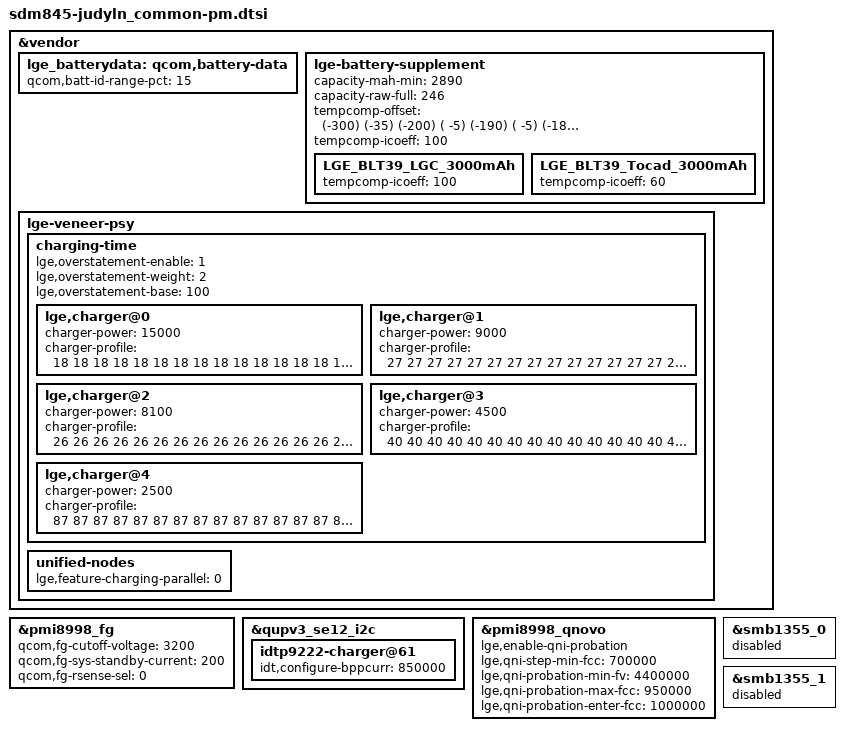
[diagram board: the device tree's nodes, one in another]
/* Copyright (c) 2017, The Linux Foundation. All rights reserved.
 *
 * This program is free software; you can redistribute it and/or modify
 * it under the terms of the GNU General Public License version 2 and
 * only version 2 as published by the Free Software Foundation.
 *
 * This program is distributed in the hope that it will be useful,
 * but WITHOUT ANY WARRANTY; without even the implied warranty of
 * MERCHANTABILITY or FITNESS FOR A PARTICULAR PURPOSE.  See the
 * GNU General Public License for more details.
 */

#include "../sdm845-judy_common/sdm845-judy_common-pm.dtsi"

&vendor {
	lge_batterydata: qcom,battery-data {
		qcom,batt-id-range-pct = <15>;

		#include "../../sdm845-battery/LGE_BLT39_LGC_3000mAh.dtsi"
		#include "../../sdm845-battery/LGE_BLT39_Tocad_3000mAh.dtsi"
	};

	lge-battery-supplement {
		capacity-mah-min = <2890>;
		capacity-raw-full = <246>;

		/* format : (temp index) (temp delta) */
		tempcomp-offset = <
			(-300) (-35)
			(-200) ( -5)
			(-190) ( -5)
			(-180)    0
			(-170)    5
			(-160)   10
			(-150)   25
			(-100)   29
			( -50)   36
			    0    38
			   50    25
			  100    21
			  150    12
			  200     2
			  250  (-10)
			  300  (-22)
			  350  (-34)
			  400  (-41)
			  450  (-48)
			  500  (-52)
			  550  (-43)
			  600  (-34)
			  700  (-10)
			  800  (-10)
			  900  (-10)
		>;
		tempcomp-icoeff = <100>;

		/* overriding by battery type */
		LGE_BLT39_LGC_3000mAh {
			tempcomp-icoeff = <100>;
		};
		LGE_BLT39_Tocad_3000mAh {
			tempcomp-icoeff = <60>;
		};
	};

	lge-veneer-psy {
		charging-time {
			#address-cells = <1>;
			#size-cells = <0>;

			lge,overstatement-enable = <1>;
			lge,overstatement-weight = <2>;
			lge,overstatement-base = <100>;

			lge,charger@0 {		//  fast charger: 9000mV * 1660mA or 5000mV * 3000mA
				charger-power = <15000>;
				charger-profile = <
					18  18  18  18  18  18  18  18  18  18  18  18  18  18  18  18
					18  18  18  18  18  18  18  18  18  18  18  18  18  18  18  18
					18  18  18  18  18  18  18  18  18  18  18  18  18  18  18  18
					18  18  18  18  18  18  18  18  18  18  18  18  18  18  18  18
					18  18  18  18  18  18  18  18  18  18  18  18  18  18  18  18
					18  18  18  18  18  18  18  18  18  18  18  18  18  18  18  18
					18  18  18  18  18  18  18  18  18  18  18  18  18  18  18  18
					18  18  18  18  18  18  18  18  18  18  18  18  18  18  18  18
					18  18  18  18  18  18  18  18  18  18  18  18  18  18  18  18
					18  18  18  18  18  18  18  18  18  18  18  18  18  18  18  18
					18  18  18  18  18  18  18  18  21  21  21  21  21  21  21  21
					21  21  21  21  21  21  21  21  21  21  21  21  21  24  24  24
					24  24  24  24  24  24  24  24  24  24  24  24  28  28  28  28
					28  28  28  28  28  29  29  38  38  38  38  38  38  38  38  38
					38  43  43  44  45  46  46  46  49  51  54  56  59  64  68  72
					76  82  88  94 101 110 113 113 113 113 113 113 113 113 113 113
				>;
			};
			lge,charger@1 {		//  dcp charger: 5000mV * 1800mA = 9W
				charger-power = <9000>;
				charger-profile = <
					27  27  27  27  27  27  27  27  27  27  27  27  27  27  27  27
					27  27  28  28  28  28  28  28  28  28  28  28  28  28  28  28
					28  28  28  28  28  28  28  28  28  28  28  28  28  28  28  28
					28  28  28  28  28  28  28  28  28  28  28  28  28  28  28  28
					28  28  28  28  29  29  29  29  29  29  29  29  29  29  29  29
					29  29  29  29  29  29  29  29  29  29  29  29  29  29  29  29
					29  29  29  29  29  29  29  29  29  29  29  29  29  29  29  29
					29  29  29  30  30  30  30  30  30  30  30  30  30  30  30  30
					30  30  30  30  30  30  30  30  30  30  30  30  30  30  30  30
					30  30  30  30  30  30  30  30  30  30  30  30  30  30  30  31
					31  31  31  31  31  31  31  31  31  31  31  31  31  31  31  31
					31  31  31  31  31  31  31  31  31  31  31  31  31  31  31  31
					31  31  31  31  31  31  31  31  32  32  32  32  32  33  33  33
					34  34  35  35  35  36  36  36  37  37  38  38  39  40  40  42
					43  44  44  45  46  47  48  48  51  52  55  57  60  65  69  73
					77  83  89  95 102 111 115 115 115 115 115 115 115 115 115 115
				>;
			};
			lge,charger@2 {		// EPP wireless charger: 9000mV * 900mA = 8.1W
				charger-power = <8100>;
				charger-profile = <
					26  26  26  26  26  26  26  26  26  26  26  26  26  26  26  26
					26  26  26  26  26  26  26  26  26  26  26  26  26  26  26  26
					26  26  26  26  26  26  26  26  26  26  26  26  26  26  26  26
					26  26  26  26  26  26  26  26  26  26  26  26  26  26  26  26
					26  26  26  26  26  26  26  26  26  26  26  26  26  26  26  26
					26  26  26  26  26  26  26  26  26  26  26  26  26  26  26  27
					27  27  27  27  27  27  27  27  27  27  27  27  27  27  27  27
					27  27  27  27  27  27  27  27  27  27  27  27  27  27  27  27
					27  27  27  27  27  27  27  27  27  27  27  27  27  27  27  27
					27  27  27  27  27  27  27  27  28  28  28  28  28  28  28  28
					28  28  28  28  28  28  28  28  28  28  28  28  28  28  28  28
					28  28  28  28  28  28  28  28  28  28  28  28  28  28  28  28
					28  28  28  28  28  28  28  28  28  28  28  28  28  29  29  29
					29  29  29  30  30  31  31  32  33  34  35  35  36  37  38  40
					41  42  43  45  47  48  50  52  54  56  59  61  64  67  71  75
					79  84  89  95 102 110 120 120 120 120 120 120 120 120 120 120
				>;
			};
			lge,charger@3 {		// BPP wireless charger: 5000mV * 900mA = 4.5W
				charger-power = <4500>;
				charger-profile = <
					40  40  40  40  40  40  40  40  40  40  40  40  40  40  40  40
					40  40  41  41  41  41  41  41  41  41  41  41  41  41  41  41
					41  41  41  41  41  41  41  41  41  41  41  41  41  42  42  42
					42  42  42  42  42  42  42  42  42  42  42  42  42  42  42  42
					42  42  42  42  42  43  43  43  43  43  43  43  43  43  43  43
					43  43  43  43  43  43  43  43  43  43  43  43  43  43  44  44
					44  44  44  44  44  44  44  44  44  44  44  44  44  44  44  44
					44  44  44  44  45  45  45  45  45  45  45  45  45  45  45  45
					45  45  45  45  45  45  45  45  45  45  46  46  46  46  46  46
					46  46  46  46  46  46  46  46  46  46  46  46  46  46  46  47
					47  47  47  47  47  47  47  47  47  47  47  47  47  47  47  47
					47  47  47  48  48  48  48  48  48  48  48  48  48  48  48  48
					48  48  48  48  48  48  49  49  49  49  49  49  49  49  49  49
					49  49  49  49  49  49  49  49  50  50  50  50  50  50  50  50
					50  50  49  50  50  51  52  54  56  59  61  64  67  70  74  78
					82  87  93  99 106 115 125 125 125 125 125 125 125 125 125 125
				>;
			};
			lge,charger@4 {		// SDP: 5000mV * 500mA = 2.5W
				charger-power = <2500>;
				charger-profile = <
					87  87  87  87  87  87  87  87  87  87  87  87  87  87  87  87
					87  87  87  87  87  87  87  87  87  87  87  87  87  87  87  87
					87  87  87  87  87  87  87  87  87  87  87  87  87  87  87  87
					87  87  87  87  87  87  87  87  87  87  87  87  87  87  87  87
					87  87  87  87  87  87  87  87  87  87  87  87  87  87  87  87
					87  87  87  87  87  87  87  87  87  87  87  87  87  87  87  87
					87  87  87  87  87  87  87  87  87  87  87  87  87  87  87  87
					87  87  87  87  87  87  87  87  87  87  87  87  87  87  87  87
					87  87  87  87  87  87  87  87  87  87  87  87  87  87  87  87
					87  87  87  87  87  87  87  87  87  87  87  87  87  87  87  87
					87  87  87  87  87  87  87  87  87  87  87  87  87  87  87  87
					87  87  87  87  87  87  87  87  87  87  87  87  87  87  87  87
					87  87  87  87  87  87  87  87  87  87  87  87  87  87  87  87
					87  87  87  87  87  87  87  87  87  87  87  87  87  87  87  87
					87  87  87  87  87  87  87  87  87  87  87  87  87  87  87  87
					87  90  96 103 111 120 124 124 124 124 124 124 124 124 124 124
				>;
			};
		};

		unified-nodes {
			lge,feature-charging-parallel = <0>;
		};
	};
};

&pmi8998_fg {
	qcom,fg-cutoff-voltage = <3200>;
	qcom,fg-sys-standby-current = <200>;

	qcom,fg-rsense-sel = <0>;
};

&qupv3_se12_i2c {
	idtp9222-charger@61 {
		idt,configure-bppcurr = <850000>;
	};
};

&pmi8998_qnovo {
	lge,enable-qni-probation;
	lge,qni-step-min-fcc = <700000>;
	lge,qni-probation-min-fv = <4400000>;
	lge,qni-probation-max-fcc = <950000>;
	lge,qni-probation-enter-fcc = <1000000>;
};

&smb1355_0 {
	status = "disabled";
};

&smb1355_1 {
	status = "disabled";
};
